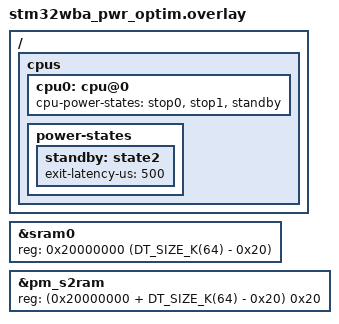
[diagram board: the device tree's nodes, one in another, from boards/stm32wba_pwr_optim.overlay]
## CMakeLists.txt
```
# SPDX-License-Identifier: Apache-2.0

cmake_minimum_required(VERSION 3.28.0)

find_package(Zephyr REQUIRED HINTS $ENV{ZEPHYR_BASE})
project(peripheral_hr)

FILE(GLOB app_sources src/*.c)
target_sources(app PRIVATE
  ${app_sources}
  )

zephyr_library_include_directories(${ZEPHYR_BASE}/samples/bluetooth)
```

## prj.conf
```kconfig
CONFIG_BT=y
CONFIG_LOG=y
CONFIG_BT_SMP=y
CONFIG_BT_SMP_APP_PAIRING_ACCEPT=y
CONFIG_BT_PERIPHERAL=y
CONFIG_BT_DIS=y
CONFIG_BT_DIS_PNP=n
CONFIG_BT_BAS=y
CONFIG_BT_HRS=y
CONFIG_BT_DEVICE_NAME="Zephyr Heartrate Sensor"
CONFIG_BT_DEVICE_APPEARANCE=833
CONFIG_REBOOT=y
```

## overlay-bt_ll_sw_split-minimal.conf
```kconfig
# Zephyr open source Bluetooth Low Energy Controller
CONFIG_BT_LL_SW_SPLIT=y

# Disable Bluetooth controller features not needed
CONFIG_BT_CTLR_CONN_PARAM_REQ=n
CONFIG_BT_CTLR_EXT_REJ_IND=n
CONFIG_BT_CTLR_PER_INIT_FEAT_XCHG=n
CONFIG_BT_CTLR_MIN_USED_CHAN=n

# Buffer sizes
CONFIG_BT_CTLR_RX_BUFFERS=1

# Use link time optimization for code size reduction
CONFIG_ISR_TABLES_LOCAL_DECLARATION=y
CONFIG_LTO=y

# Generate .lst file, to find HCI h/w error event given PC
CONFIG_OUTPUT_DISASSEMBLY=y
CONFIG_OUTPUT_DISASSEMBLY_WITH_SOURCE=y
```

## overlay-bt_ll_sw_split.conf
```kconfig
# Configuration file to be used as an overlay to the hci_ipc sample for multi-core boards

CONFIG_BT_EXT_ADV=y

# Enable Coded PHY support
CONFIG_BT_CTLR_PHY_CODED=y

# Increase Advertising Data Length, as Complete Local Name too needs to be
# placed in the AUX_ADV_IND PDU compared to when it is placed in ADV_SCAN_IND
# PDU in the case of legacy advertising.
CONFIG_BT_CTLR_ADV_DATA_LEN_MAX=36
```

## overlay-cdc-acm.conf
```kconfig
CONFIG_SERIAL=y
CONFIG_CONSOLE=y
CONFIG_UART_CONSOLE=y
CONFIG_STDOUT_CONSOLE=y
CONFIG_UART_LINE_CTRL=y

CONFIG_USB_DEVICE_STACK_NEXT=y
CONFIG_CDC_ACM_SERIAL_INITIALIZE_AT_BOOT=y

CONFIG_REBOOT=y
CONFIG_BT_SECURITY_ERR_TO_STR=y
```

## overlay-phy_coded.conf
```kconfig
CONFIG_BT_EXT_ADV=y

# Enable Coded PHY support
CONFIG_BT_CTLR_PHY_CODED=y

# Increase Advertising Data Length, as Complete Local Name too needs to be
# placed in the AUX_ADV_IND PDU compared to when it is placed in ADV_SCAN_IND
# PDU in the case of legacy advertising.
CONFIG_BT_CTLR_ADV_DATA_LEN_MAX=36
```

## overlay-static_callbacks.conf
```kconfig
# Disable connection dynamic callbacks
CONFIG_BT_CONN_DYNAMIC_CALLBACKS=n
```

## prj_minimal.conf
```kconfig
CONFIG_BT=y
CONFIG_BT_SMP=y
CONFIG_BT_PERIPHERAL=y
CONFIG_BT_DIS=y
CONFIG_BT_DIS_PNP=n
CONFIG_BT_BAS=y
CONFIG_BT_HRS=y
CONFIG_BT_DEVICE_NAME="Zephyr Heartrate Sensor"
CONFIG_BT_DEVICE_APPEARANCE=833
CONFIG_BT_LIM_ADV=n

# Drivers and peripherals
CONFIG_I2C=n
CONFIG_WATCHDOG=n
CONFIG_PINCTRL=n
CONFIG_SPI=n
CONFIG_GPIO=n
CONFIG_SERIAL=n

# Power management
CONFIG_PM=n

# Interrupts
CONFIG_DYNAMIC_INTERRUPTS=n
CONFIG_IRQ_OFFLOAD=n

# Memory protection
CONFIG_THREAD_STACK_INFO=n
CONFIG_THREAD_CUSTOM_DATA=n
CONFIG_FPU=n

# Boot
CONFIG_BOOT_BANNER=n
CONFIG_BOOT_DELAY=0

# Console
CONFIG_CONSOLE=n
CONFIG_UART_CONSOLE=n
CONFIG_STDOUT_CONSOLE=n
CONFIG_PRINTK=n
CONFIG_EARLY_CONSOLE=n

# Build
CONFIG_SIZE_OPTIMIZATIONS=y

# ARM
CONFIG_ARM_MPU=n
CONFIG_BUILTIN_STACK_GUARD=n

# In order to correctly tune the stack sizes for the threads the following
# Configurations can enabled to print the current use:
# CONFIG_THREAD_NAME=y
# CONFIG_THREAD_ANALYZER=y
# CONFIG_THREAD_ANALYZER_AUTO=y
# CONFIG_THREAD_ANALYZER_RUN_UNLOCKED=y
# CONFIG_THREAD_ANALYZER_USE_PRINTK=y
# CONFIG_THREAD_ANALYZER_AUTO_INTERVAL=20
# CONFIG_CONSOLE=y
# CONFIG_UART_CONSOLE=y
# CONFIG_SERIAL=y
# CONFIG_PRINTK=y

# Example output of thread analyzer
# BT RX               : STACK: unused 576 usage 448 / 1024 (43 %); CPU: 0 %
# BT RX pri           : STACK: unused 260 usage 188 / 448 (41 %); CPU: 0 %
# BT ECC              : STACK: unused 256 usage 888 / 1144 (77 %); CPU: 1 %
# BT TX               : STACK: unused 296 usage 344 / 640 (53 %); CPU: 0 %
# thread_analyzer     : STACK: unused 128 usage 384 / 512 (75 %); CPU: 1 %
# sysworkq            : STACK: unused 856 usage 168 / 1024 (16 %); CPU: 0 %
# logging             : STACK: unused 232 usage 536 / 768 (69 %); CPU: 0 %
# idle 00             : STACK: unused 208 usage 48 / 256 (18 %); CPU: 97 %
# main                : STACK: unused 576 usage 448 / 1024 (43 %); CPU: 0 %
CONFIG_BT_RX_STACK_SIZE=1024
CONFIG_BT_HCI_TX_STACK_SIZE_WITH_PROMPT=y
CONFIG_BT_HCI_TX_STACK_SIZE=640
CONFIG_IDLE_STACK_SIZE=128
CONFIG_MAIN_STACK_SIZE=640
CONFIG_ISR_STACK_SIZE=1024

# Disable features not needed
CONFIG_TIMESLICING=n
CONFIG_COMMON_LIBC_MALLOC=n
CONFIG_LOG=n
CONFIG_ASSERT=n

# Disable Bluetooth features not needed
# CONFIG_BT_DEBUG_NONE=y
CONFIG_BT_ASSERT=n
CONFIG_BT_DATA_LEN_UPDATE=n
CONFIG_BT_PHY_UPDATE=n
CONFIG_BT_GATT_CACHING=n
CONFIG_BT_GATT_SERVICE_CHANGED=n
CONFIG_BT_GAP_PERIPHERAL_PREF_PARAMS=n
CONFIG_BT_HCI_VS=n
CONFIG_BT_CONN_DYNAMIC_CALLBACKS=n

# Reduce Bluetooth buffers
CONFIG_BT_BUF_EVT_DISCARDABLE_COUNT=1
CONFIG_BT_BUF_EVT_DISCARDABLE_SIZE=45
CONFIG_BT_BUF_EVT_RX_COUNT=4

CONFIG_BT_L2CAP_TX_BUF_COUNT=2
CONFIG_BT_BUF_ACL_TX_COUNT=3
CONFIG_BT_BUF_ACL_TX_SIZE=27

# Limit the number of key slots in PSA Crypto core to reduce
# RAM footprint. Each key the Host uses lives for one operation only: at
# most one key pair, for generating the public key or a DH key, and one
# short-lived key of a pairing computation exist at a time, as nothing
# else in this configuration uses the key store. Three slots leave one
# to spare.
CONFIG_MBEDTLS_PSA_KEY_SLOT_COUNT=3

# This is required because otherwise there won't be
# __heap_start/__heap_end symbols defined in the build. This
# is due to Mbed TLS which at boot uses standard calloc/free
# functions and only after the initialization done from Zephyr
# it switches to its internal memory management functions.
CONFIG_COMMON_LIBC_MALLOC=y
```

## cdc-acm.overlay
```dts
/*
 * Copyright The Zephyr Project Contributors
 *
 * SPDX-License-Identifier: Apache-2.0
 */

/ {
	chosen {
		zephyr,console = &cdc_acm_uart0;
	};
};

&zephyr_udc0 {
	cdc_acm_uart0: cdc_acm_uart0 {
		compatible = "zephyr,cdc-acm-uart";
	};
};
```

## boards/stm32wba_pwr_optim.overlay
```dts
/*
 * SPDX-License-Identifier: Apache-2.0
 *
 * Copyright (c) 2025 STMicroelectronics
 */
/ {
	/* Change min residency time to ease power consumption measurement */
	cpus {
		cpu0: cpu@0 {
			cpu-power-states = <&stop0 &stop1 &standby>;
		};

		power-states {
			standby: state2 {
				exit-latency-us = <500>;
			};
		};
	};
};

/*
 * Reduce flash usage for the power-optimized setup so the full flash is
 * not used when it is not necessary, helping reduce power consumption.
 * the pm_S2ram node is moved accordingly to the end of the used flash.
 */
&sram0 {
	reg = <0x20000000 (DT_SIZE_K(64) - 0x20)>;
};

&pm_s2ram {
	reg = <(0x20000000 + DT_SIZE_K(64) - 0x20) 0x20>;
};
```

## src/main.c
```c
/* main.c - Application main entry point */

/*
 * Copyright (c) 2024 Nordic Semiconductor ASA
 * Copyright (c) 2015-2016 Intel Corporation
 *
 * SPDX-License-Identifier: Apache-2.0
 */

#include <zephyr/device.h>
#include <zephyr/devicetree.h>
#include <zephyr/drivers/uart.h>
#include <zephyr/sys/reboot.h>

#include <zephyr/bluetooth/bluetooth.h>
#include <zephyr/bluetooth/hci.h>
#include <zephyr/bluetooth/conn.h>
#include <zephyr/bluetooth/uuid.h>
#include <zephyr/bluetooth/gatt.h>
#include <zephyr/bluetooth/services/bas.h>
#include <zephyr/bluetooth/services/hrs.h>

static bool hrf_ntf_enabled;

static const struct bt_data ad[] = {
	BT_DATA_BYTES(BT_DATA_FLAGS, (BT_LE_AD_GENERAL | BT_LE_AD_NO_BREDR)),
	BT_DATA_BYTES(BT_DATA_UUID16_ALL,
		      BT_UUID_16_ENCODE(BT_UUID_HRS_VAL),
		      BT_UUID_16_ENCODE(BT_UUID_BAS_VAL),
		      BT_UUID_16_ENCODE(BT_UUID_DIS_VAL)),
#if defined(CONFIG_BT_EXT_ADV)
	BT_DATA(BT_DATA_NAME_COMPLETE, CONFIG_BT_DEVICE_NAME, sizeof(CONFIG_BT_DEVICE_NAME) - 1),
#endif /* CONFIG_BT_EXT_ADV */
};

#if !defined(CONFIG_BT_EXT_ADV)
static const struct bt_data sd[] = {
	BT_DATA(BT_DATA_NAME_COMPLETE, CONFIG_BT_DEVICE_NAME, sizeof(CONFIG_BT_DEVICE_NAME) - 1),
};
#endif /* !CONFIG_BT_EXT_ADV */

enum {
	STATE_CONNECTED,
	STATE_DISCONNECTED,

	STATE_BITS,
};

static ATOMIC_DEFINE(state, STATE_BITS);

static struct k_work_delayable security_work;
static struct k_spinlock security_lock;
static struct bt_conn *security_pending_conn;

#define SECURITY_REQUEST_DELAY K_SECONDS(1)

static void cancel_security_request(struct bt_conn *conn)
{
	struct bt_conn *pending_conn = NULL;
	k_spinlock_key_t key;

	(void)k_work_cancel_delayable(&security_work);

	key = k_spin_lock(&security_lock);
	if (security_pending_conn == conn) {
		pending_conn = security_pending_conn;
		security_pending_conn = NULL;
	}
	k_spin_unlock(&security_lock, key);

	if (pending_conn != NULL) {
		bt_conn_unref(pending_conn);
	}
}

static void security_work_handler(struct k_work *work)
{
	struct bt_conn *conn;
	k_spinlock_key_t key;
	int err;

	ARG_UNUSED(work);

	key = k_spin_lock(&security_lock);
	conn = security_pending_conn;
	security_pending_conn = NULL;
	k_spin_unlock(&security_lock, key);

	if (conn == NULL) {
		return;
	}

	if (bt_conn_get_security(conn) < BT_SECURITY_L2) {
		err = bt_conn_set_security(conn, BT_SECURITY_L2);
		if (err != 0) {
			printk("Failed to request security (err %d)\n", err);
		}
	}

	bt_conn_unref(conn);
}

static void connected(struct bt_conn *conn, uint8_t err)
{
	if (err) {
		printk("Connection failed, err 0x%02x %s\n", err, bt_hci_err_to_str(err));
	} else {
		struct bt_conn *old_conn = NULL;
		k_spinlock_key_t key;

		printk("Connected\n");

		if (bt_conn_get_security(conn) < BT_SECURITY_L2) {
			key = k_spin_lock(&security_lock);
			old_conn = security_pending_conn;
			security_pending_conn = bt_conn_ref(conn);
			k_spin_unlock(&security_lock, key);

			if (old_conn != NULL) {
				bt_conn_unref(old_conn);
			}

			(void)k_work_reschedule(&security_work, SECURITY_REQUEST_DELAY);
		}

		(void)atomic_set_bit(state, STATE_CONNECTED);
	}
}

#define BT_UUID_SEC_STATUS_SVC_VAL \
	BT_UUID_128_ENCODE(0x6b1f0001, 0x4c2a, 0x4f7e, 0x9d3b, 0x5a8c1e2f7a10)
#define BT_UUID_SEC_STATUS_VAL \
	BT_UUID_128_ENCODE(0x6b1f0002, 0x4c2a, 0x4f7e, 0x9d3b, 0x5a8c1e2f7a10)

static struct bt_uuid_128 sec_status_svc_uuid = BT_UUID_INIT_128(BT_UUID_SEC_STATUS_SVC_VAL);
static struct bt_uuid_128 sec_status_uuid = BT_UUID_INIT_128(BT_UUID_SEC_STATUS_VAL);

/* Payload: [0] = achieved security level, [1] = enum bt_security_err (0 on success) */
static uint8_t sec_status[2];

static ssize_t read_sec_status(struct bt_conn *conn, const struct bt_gatt_attr *attr,
			       void *buf, uint16_t len, uint16_t offset)
{
	return bt_gatt_attr_read(conn, attr, buf, len, offset, sec_status, sizeof(sec_status));
}

static void sec_status_ccc_changed(const struct bt_gatt_attr *attr, uint16_t value)
{
	printk("Security status notification %s\n",
	       value == BT_GATT_CCC_NOTIFY ? "enabled" : "disabled");
}

/* Neither the characteristic nor its CCC require encryption, so a central can
 * subscribe and receive the failure over an unencrypted link.
 */
BT_GATT_SERVICE_DEFINE(sec_status_svc,
	BT_GATT_PRIMARY_SERVICE(&sec_status_svc_uuid),
	BT_GATT_CHARACTERISTIC(&sec_status_uuid.uuid, BT_GATT_CHRC_READ | BT_GATT_CHRC_NOTIFY,
			       BT_GATT_PERM_READ, read_sec_status, NULL, NULL),
	BT_GATT_CCC(sec_status_ccc_changed, BT_GATT_PERM_READ | BT_GATT_PERM_WRITE),
);

/* Delay so the status notification is sent before bt_unpair() disconnects the peer */
#define UNPAIR_DELAY K_MSEC(500)

static struct k_work_delayable unpair_work;
static bt_addr_le_t unpair_addr;
static uint8_t unpair_id;

static void unpair_work_handler(struct k_work *work)
{
	char addr_str[BT_ADDR_LE_STR_LEN];
	int unpair_err;

	bt_addr_le_to_str(&unpair_addr, addr_str, sizeof(addr_str));

	unpair_err = bt_unpair(unpair_id, &unpair_addr);
	if (unpair_err != 0) {
		printk("Failed to remove bond for %s (err %d)\n", addr_str, unpair_err);
	} else {
		printk("Removed bond for %s, rebooting\n", addr_str);
		/* Let the console flush before the reset */
		k_sleep(K_MSEC(100));
		sys_reboot(SYS_REBOOT_COLD);
	}
}

static void security_changed(struct bt_conn *conn, bt_security_t level,
			     enum bt_security_err err)
{
	struct bt_conn_info info;
	int notify_err;

	cancel_security_request(conn);

	if (err == 0) {
		printk("Security changed: %s level %u\n", bt_conn_dst_str(conn), level);
	} else {
		printk("Security failed: %s level %u err %s (%d)\n", bt_conn_dst_str(conn), level,
		       bt_security_err_to_str(err), err);
	}

	sec_status[0] = (uint8_t)level;
	sec_status[1] = (uint8_t)err;

	notify_err = bt_gatt_notify_uuid(conn, &sec_status_uuid.uuid, &sec_status_svc.attrs[0],
					 sec_status, sizeof(sec_status));
	if (notify_err != 0 && notify_err != -ENOTCONN) {
		printk("Security status notify failed (err %d)\n", notify_err);
	}

	if (err != 0 && bt_conn_get_info(conn, &info) == 0) {
		unpair_id = info.id;
		bt_addr_le_copy(&unpair_addr, bt_conn_get_dst(conn));
		k_work_reschedule(&unpair_work, UNPAIR_DELAY);
	}
}

static void disconnected(struct bt_conn *conn, uint8_t reason)
{
	printk("Disconnected, reason 0x%02x %s\n", reason, bt_hci_err_to_str(reason));

	cancel_security_request(conn);

	(void)atomic_set_bit(state, STATE_DISCONNECTED);
}

BT_CONN_CB_DEFINE(conn_callbacks) = {
	.connected = connected,
	.disconnected = disconnected,
	.security_changed = security_changed,
};

static void hrs_ntf_changed(bool enabled)
{
	hrf_ntf_enabled = enabled;

	printk("HRS notification status changed: %s\n",
	       enabled ? "enabled" : "disabled");
}

static struct bt_hrs_cb hrs_cb = {
	.ntf_changed = hrs_ntf_changed,
};

static void auth_cancel(struct bt_conn *conn)
{
	printk("Pairing cancelled: %s\n", bt_conn_dst_str(conn));
}

static enum bt_security_err pairing_accept(
	struct bt_conn *conn, const struct bt_conn_pairing_feat *const feat)
{
	ARG_UNUSED(feat);

	printk("Peer initiated pairing: %s\n", bt_conn_dst_str(conn));
	cancel_security_request(conn);

	return BT_SECURITY_ERR_SUCCESS;
}

static struct bt_conn_auth_cb auth_cb_display = {
	.cancel = auth_cancel,
	.pairing_accept = pairing_accept,
};

static void bas_notify(void)
{
	uint8_t battery_level = bt_bas_get_battery_level();

	battery_level--;

	if (!battery_level) {
		battery_level = 100U;
	}

	bt_bas_set_battery_level(battery_level);
}

static void hrs_notify(void)
{
	static uint8_t heartrate = 90U;

	/* Heartrate measurements simulation */
	heartrate++;
	if (heartrate == 160U) {
		heartrate = 90U;
	}

	if (hrf_ntf_enabled) {
		bt_hrs_notify(heartrate);
	}
}

#if defined(CONFIG_GPIO)
/* The devicetree node identifier for the "led0" alias. */
#define LED0_NODE DT_ALIAS(led0)

#if DT_NODE_HAS_STATUS_OKAY(LED0_NODE)
#include <zephyr/drivers/gpio.h>
#define HAS_LED     1
static const struct gpio_dt_spec led = GPIO_DT_SPEC_GET(LED0_NODE, gpios);
#define BLINK_ONOFF K_MSEC(500)

static struct k_work_delayable blink_work;
static bool                  led_is_on;

static void blink_timeout(struct k_work *work)
{
	led_is_on = !led_is_on;
	gpio_pin_set(led.port, led.pin, (int)led_is_on);

	k_work_schedule(&blink_work, BLINK_ONOFF);
}

static int blink_setup(void)
{
	int err;

	printk("Checking LED device...");
	if (!gpio_is_ready_dt(&led)) {
		printk("failed.\n");
		return -EIO;
	}
	printk("done.\n");

	printk("Configuring GPIO pin...");
	err = gpio_pin_configure_dt(&led, GPIO_OUTPUT_ACTIVE);
	if (err) {
		printk("failed.\n");
		return -EIO;
	}
	printk("done.\n");

	k_work_init_delayable(&blink_work, blink_timeout);

	return 0;
}

static void blink_start(void)
{
	printk("Start blinking LED...\n");
	led_is_on = false;
	gpio_pin_set(led.port, led.pin, (int)led_is_on);
	k_work_schedule(&blink_work, BLINK_ONOFF);
}

static void blink_stop(void)
{
	struct k_work_sync work_sync;

	printk("Stop blinking LED.\n");
	k_work_cancel_delayable_sync(&blink_work, &work_sync);

	/* Keep LED on */
	led_is_on = true;
	gpio_pin_set(led.port, led.pin, (int)led_is_on);
}
#endif /* LED0_NODE */
#endif /* CONFIG_GPIO */

#if defined(CONFIG_UART_LINE_CTRL) && DT_HAS_CHOSEN(zephyr_console)
/* Wait for a host to open the console port, otherwise early output is lost */
static void console_wait_dtr(void)
{
	const struct device *const console = DEVICE_DT_GET(DT_CHOSEN(zephyr_console));
	uint32_t dtr = 0U;

	if (!device_is_ready(console)) {
		return;
	}

	for (int i = 0; i < 100 && dtr == 0U; i++) {
		(void)uart_line_ctrl_get(console, UART_LINE_CTRL_DTR, &dtr);
		k_sleep(K_MSEC(100));
	}
}
#endif

int main(void)
{
	int err;

#if defined(CONFIG_UART_LINE_CTRL) && DT_HAS_CHOSEN(zephyr_console)
	console_wait_dtr();
#endif

	err = bt_enable(NULL);
	if (err) {
		printk("Bluetooth init failed (err %d)\n", err);
		return 0;
	}

	printk("Bluetooth initialized\n");

	bt_conn_auth_cb_register(&auth_cb_display);

	k_work_init_delayable(&security_work, security_work_handler);
	k_work_init_delayable(&unpair_work, unpair_work_handler);

	bt_hrs_cb_register(&hrs_cb);

#if !defined(CONFIG_BT_EXT_ADV)
	printk("Starting Legacy Advertising (connectable and scannable)\n");
	err = bt_le_adv_start(BT_LE_ADV_CONN_FAST_1, ad, ARRAY_SIZE(ad), sd, ARRAY_SIZE(sd));
	if (err) {
		printk("Advertising failed to start (err %d)\n", err);
		return 0;
	}

#else /* CONFIG_BT_EXT_ADV */
	struct bt_le_adv_param adv_param = {
		.id = BT_ID_DEFAULT,
		.sid = 0U,
		.secondary_max_skip = 0U,
		.options = (BT_LE_ADV_OPT_EXT_ADV | BT_LE_ADV_OPT_CONN | BT_LE_ADV_OPT_CODED),
		.interval_min = BT_GAP_ADV_FAST_INT_MIN_2,
		.interval_max = BT_GAP_ADV_FAST_INT_MAX_2,
		.peer = NULL,
	};
	struct bt_le_ext_adv *adv;

	printk("Creating a Coded PHY connectable non-scannable advertising set\n");
	err = bt_le_ext_adv_create(&adv_param, NULL, &adv);
	if (err) {
		printk("Failed to create Coded PHY extended advertising set (err %d)\n", err);

		printk("Creating a non-Coded PHY connectable non-scannable advertising set\n");
		adv_param.options &= ~BT_LE_ADV_OPT_CODED;
		err = bt_le_ext_adv_create(&adv_param, NULL, &adv);
		if (err) {
			printk("Failed to create extended advertising set (err %d)\n", err);
			return 0;
		}
	}

	printk("Setting extended advertising data\n");
	err = bt_le_ext_adv_set_data(adv, ad, ARRAY_SIZE(ad), NULL, 0);
	if (err) {
		printk("Failed to set extended advertising data (err %d)\n", err);
		return 0;
	}

	printk("Starting Extended Advertising (connectable non-scannable)\n");
	err = bt_le_ext_adv_start(adv, BT_LE_EXT_ADV_START_DEFAULT);
	if (err) {
		printk("Failed to start extended advertising set (err %d)\n", err);
		return 0;
	}
#endif /* CONFIG_BT_EXT_ADV */

	printk("Advertising successfully started\n");

#if defined(HAS_LED)
	err = blink_setup();
	if (err) {
		return 0;
	}

	blink_start();
#endif /* HAS_LED */

	/* Implement notification. */
	while (1) {
		k_sleep(K_SECONDS(1));

		/* Heartrate measurements simulation */
		hrs_notify();

		/* Battery level simulation */
		bas_notify();

		if (atomic_test_and_clear_bit(state, STATE_CONNECTED)) {
			/* Connected callback executed */

#if defined(HAS_LED)
			blink_stop();
#endif /* HAS_LED */
		} else if (atomic_test_and_clear_bit(state, STATE_DISCONNECTED)) {
#if !defined(CONFIG_BT_EXT_ADV)
			printk("Starting Legacy Advertising (connectable and scannable)\n");
			err = bt_le_adv_start(BT_LE_ADV_CONN_FAST_1, ad, ARRAY_SIZE(ad), sd,
					      ARRAY_SIZE(sd));
			if (err) {
				printk("Advertising failed to start (err %d)\n", err);
				return 0;
			}

#else /* CONFIG_BT_EXT_ADV */
			printk("Starting Extended Advertising (connectable and non-scannable)\n");
			err = bt_le_ext_adv_start(adv, BT_LE_EXT_ADV_START_DEFAULT);
			if (err) {
				printk("Failed to start extended advertising set (err %d)\n", err);
				return 0;
			}
#endif /* CONFIG_BT_EXT_ADV */

#if defined(HAS_LED)
			blink_start();
#endif /* HAS_LED */
		}
	}

	return 0;
}
```
